# ATBTLC1000WLCSP device description
Architecture: CORTEX-M0; Family: SAMB; Series: SAMB11
Registers are 32-bit, read-write, reset 0x0 unless marked. A register's access mark holds for its fields unless they carry their own. Offsets are from the block's base; [hi:lo] are bit positions; {n}, {i} and the like mark numbered series; 'fields as' and 'values as' point back to an identical list.

## TIMER — ARM General Purpose Timer
Instances: TIMER0 0x40000000
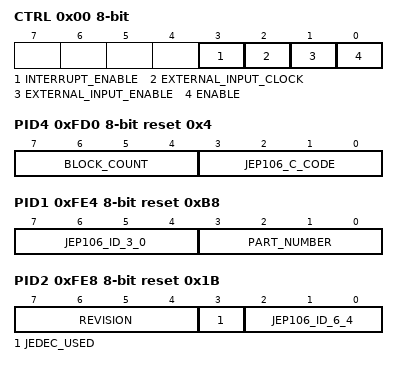
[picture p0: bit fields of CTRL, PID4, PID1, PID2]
0x00 CTRL 8-bit — Timer Control
  [3] INTERRUPT_ENABLE — Enable Timer Interrupt
  [2] EXTERNAL_INPUT_CLOCK — Select external input as clock
  [1] EXTERNAL_INPUT_ENABLE — Select external input as enable
  [0] ENABLE — Enable Timer Operation
0x04 VALUE — Current Value
0x08 RELOAD — Reload Value
0x0C INTSTATUSCLEAR 8-bit — Timer Interrupt, write 1 to clear
  [0] INTSTATUSCLEAR
0xFD0 PID4 8-bit ro reset 0x4 — Peripheral ID Register 4
  [7:4] BLOCK_COUNT, [3:0] JEP106_C_CODE
{0xFC0+4i} PID{i} 8-bit ro (i=5..7) — Peripheral ID Register {i}
0xFE0 PID0 8-bit ro reset 0x22 — Peripheral ID Register 0
  [7:0] PART_NUMBER — Part Number Bits 7:0
0xFE4 PID1 8-bit ro reset 0xB8 — Peripheral ID Register 1
  [7:4] JEP106_ID_3_0 — JEP106 ID Bits 3:0
  [3:0] PART_NUMBER — Part Number Bits 11:8
0xFE8 PID2 8-bit ro reset 0x1B — Peripheral ID Register 2
  [7:4] REVISION
  [3] JEDEC_USED
  [2:0] JEP106_ID_6_4 — JEP106 ID Bits 6:4
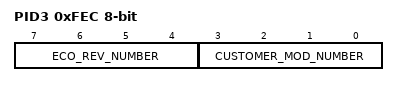
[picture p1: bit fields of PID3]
0xFEC PID3 8-bit ro — Peripheral ID Register 3
  [7:4] ECO_REV_NUMBER — ECO Revision Number
  [3:0] CUSTOMER_MOD_NUMBER — Customer Modification Number
0xFF0 CID0 8-bit ro reset 0xD — Component ID Register 0
0xFF4 CID1 8-bit ro reset 0xF0 — Component ID Register 1
0xFF8 CID2 8-bit ro reset 0x5 — Component ID Register 2
0xFFC CID3 8-bit ro reset 0xB1 — Component ID Register 3

## DUALTIMER — ARM General Purpose Dual Timer
Instances: DUALTIMER0 0x40001000
0x00 TIMER1LOAD
0x04 TIMER1VALUE ro reset 0xFFFFFFFF — Timer 1 Current Value Register
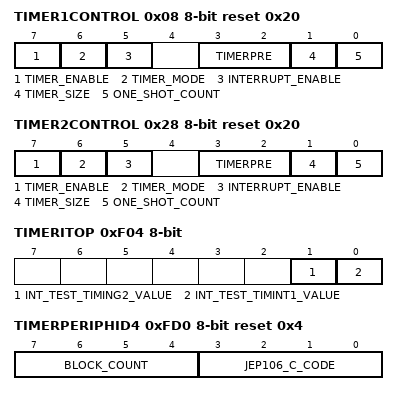
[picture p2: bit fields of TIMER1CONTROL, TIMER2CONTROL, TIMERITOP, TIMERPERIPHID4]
0x08 TIMER1CONTROL 8-bit reset 0x20
  [7] TIMER_ENABLE — Active High Timer Enable
  [6] TIMER_MODE — Mode Bit
    0=Free-Running Mode; 1=Periodic Mode
  [5] INTERRUPT_ENABLE — Active High Interrupt Enable Bit
  [3:2] TIMERPRE — Prescale Bits
    0=0 Stages, Clock Divided by 1; 1=4 Stages, Clock Divided by 16; 2=8 Stages, Clock Divided by 256; 3=Undefined, do not use
  [1] TIMER_SIZE
    0=16-bit Counter; 1=32-bit Counter
  [0] ONE_SHOT_COUNT — Mode Select
    0=Wrapping Mode; 1=One-Shot Mode
0x0C TIMER1INTCLR 8-bit wo — Timer 1 Interrupt Clear Register
  [0] TIMER1INTCLR
0x10 TIMER1RIS 8-bit ro — Timer 1 Raw Interrupt Status Register
  [0] TIMER1RIS
0x14 TIMER1MIS 8-bit ro — Timer 1 Masked Interrupt Status Register
  [0] TIMER1MIS
0x18 TIMER1BGLOAD — Timer 1 Background Load Register (Reload Value for Period Mode)
0x20 TIMER2LOAD
0x24 TIMER2VALUE ro reset 0xFFFFFFFF — Timer 2 Current Value Register
0x28 TIMER2CONTROL 8-bit reset 0x20
  fields as TIMER1CONTROL
0x2C TIMER2INTCLR 8-bit wo — Timer 2 Interrupt Clear Register
  [0] TIMER2INTCLR
0x30 TIMER2RIS 8-bit ro — Timer 2 Raw Interrupt Status Register
  [0] TIMER2RIS
0x34 TIMER2MIS 8-bit ro — Timer 2 Masked Interrupt Status Register
  [0] TIMER2MIS
0x38 TIMER2BGLOAD — Timer 2 Background Load Register (Reload Value for Period Mode)
0xF00 TIMERITCR 8-bit — Integration Test Control Register
  [0] TIMERITCR
0xF04 TIMERITOP 8-bit wo — Integration Test Output Set Register
  [1] INT_TEST_TIMING2_VALUE — Value Output on TIMINT2 in Integration Test Mode
  [0] INT_TEST_TIMINT1_VALUE — Value Output on TIMINT1 in Integration Test Mode
0xFD0 TIMERPERIPHID4 8-bit ro reset 0x4 — Peripheral ID Register 4
  [7:4] BLOCK_COUNT, [3:0] JEP106_C_CODE
{0xFC0+4i} TIMERPERIPHID{i} 8-bit ro (i=5..7) — Peripheral ID Register {i}
0xFE0 TIMERPERIPHID0 8-bit ro reset 0x23 — Peripheral ID Register 0
  [7:0] PART_NUMBER — Part Number Bits 7:0
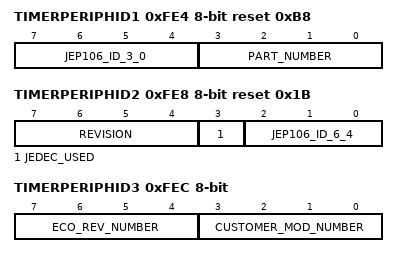
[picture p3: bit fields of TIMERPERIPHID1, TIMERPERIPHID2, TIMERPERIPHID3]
0xFE4 TIMERPERIPHID1 8-bit ro reset 0xB8 — Peripheral ID Register 1
  [7:4] JEP106_ID_3_0 — JEP106 ID Bits 3:0
  [3:0] PART_NUMBER — Part Number Bits 11:8
0xFE8 TIMERPERIPHID2 8-bit ro reset 0x1B — Peripheral ID Register 2
  [7:4] REVISION
  [3] JEDEC_USED
  [2:0] JEP106_ID_6_4 — JEP106 ID Bits 6:4
0xFEC TIMERPERIPHID3 8-bit ro — Peripheral ID Register 3
  [7:4] ECO_REV_NUMBER — ECO Revision Number
  [3:0] CUSTOMER_MOD_NUMBER — Customer Modification Number
0xFF0 TIMERPCELLID0 8-bit ro reset 0xD — Component ID Register 0
0xFF4 TIMERPCELLID1 8-bit ro reset 0xF0 — Component ID Register 1
0xFF8 TIMERPCELLID2 8-bit ro reset 0x5 — Component ID Register 2
0xFFC TIMERPCELLID3 8-bit ro reset 0xB1 — Component ID Register 3
